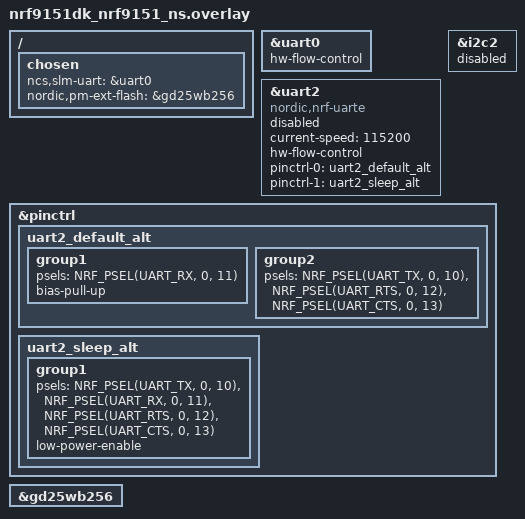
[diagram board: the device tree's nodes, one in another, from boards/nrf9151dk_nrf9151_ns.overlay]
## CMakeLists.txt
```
#
# Copyright (c) 2019 Nordic Semiconductor
#
# SPDX-License-Identifier: LicenseRef-Nordic-5-Clause
#

cmake_minimum_required(VERSION 3.20.0)

find_package(Zephyr REQUIRED HINTS $ENV{ZEPHYR_BASE})
project(serial_lte_modem)

# NORDIC SDK APP START
target_sources(app PRIVATE src/main.c)
target_sources(app PRIVATE src/slm_util.c)
target_sources(app PRIVATE src/slm_settings.c)
target_sources(app PRIVATE src/slm_at_host.c)
target_sources(app PRIVATE src/slm_at_commands.c)
target_sources_ifdef(CONFIG_SLM_SOCKET app PRIVATE src/slm_at_socket.c)
target_sources_ifdef(CONFIG_SLM_TCP_PROXY app PRIVATE src/slm_at_tcp_proxy.c)
target_sources_ifdef(CONFIG_SLM_UDP_PROXY app PRIVATE src/slm_at_udp_proxy.c)
target_sources_ifdef(CONFIG_SLM_ICMP app PRIVATE src/slm_at_icmp.c)
target_sources(app PRIVATE src/slm_at_fota.c)
target_sources(app PRIVATE src/slm_uart_handler.c)
# NORDIC SDK APP END
target_sources_ifdef(CONFIG_SLM_SMS app PRIVATE src/slm_at_sms.c)
target_sources_ifdef(CONFIG_SLM_PPP app PRIVATE src/slm_ppp.c)
target_sources_ifdef(CONFIG_SLM_CMUX app PRIVATE src/slm_cmux.c)

add_subdirectory_ifdef(CONFIG_SLM_GNSS src/gnss)
add_subdirectory_ifdef(CONFIG_SLM_NRF_CLOUD src/nrfcloud)
add_subdirectory_ifdef(CONFIG_SLM_MQTTC src/mqtt_c)
add_subdirectory_ifdef(CONFIG_SLM_HTTPC src/http_c)
add_subdirectory_ifdef(CONFIG_SLM_TWI src/twi)
add_subdirectory_ifdef(CONFIG_SLM_GPIO src/gpio)
add_subdirectory_ifdef(CONFIG_SLM_CARRIER src/lwm2m_carrier)
add_subdirectory_ifdef(CONFIG_SLM_NATIVE_TLS src/nativetls)
if (CONFIG_SLM_FTPC OR CONFIG_SLM_TFTPC)
        add_subdirectory(src/ftp_c)
endif()

zephyr_include_directories(src)
```

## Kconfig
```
#
# Copyright (c) 2019 Nordic Semiconductor
#
# SPDX-License-Identifier: LicenseRef-Nordic-5-Clause
#

source "Kconfig.zephyr"

menu "Nordic Serial LTE Modem"

config SLM_CUSTOMER_VERSION
	string "Customer version string"
	help
	   This version is reported together with baseline versions by AT command "#XSLMVER".

config SLM_AT_MAX_PARAM
	int "Maximum number of parameters in AT command"
	default 42

#
# external XTAL for UART
#
config SLM_EXTERNAL_XTAL
	bool "Use external XTAL for UARTE"
	default y

#
# AT command terminator
#
choice
	prompt "Termination mode"
	default SLM_CR_LF_TERMINATION
	help
		Sets the command terminator used by the serial terminal.
		Available options are:
		-  CR termination
		-  LF termination
		-  CR+LF termination
	config SLM_CR_TERMINATION
		bool "CR termination"
	config SLM_LF_TERMINATION
		bool "LF termination"
	config SLM_CR_LF_TERMINATION
		bool "CR+LF termination"
endchoice

#
# UART buffers (when CMUX is not in use)
#
config SLM_UART_RX_BUF_COUNT
	int "Receive buffers for UART"
	range 2 4
	default 3
	help
	  Amount of buffers for receiving (RX) UART traffic.
	  If the buffers are full, UART RX will be disabled until the buffers are processed.
	  These buffers are not used when CMUX is in use.

config SLM_UART_RX_BUF_SIZE
	int "Receive buffer size for UART"
	range 128 4096
	default 256
	help
	  Amount of received (RX), unprocessed, UART traffic that can be held by single buffer.
	  These buffers are not used when CMUX is in use.

config SLM_UART_TX_BUF_SIZE
	int "Send buffer size for UART"
	range 128 4096
	default 256
	help
	  Amount of UART traffic waiting to be sent (TX), that can be held.
	  If the buffers are full, will send synchronously.
	  These buffers are not used when CMUX is in use.

#
# GPIO functionality
#
config SLM_START_SLEEP
	bool "Enter sleep on startup"
	help
	  If enabled, the SiP is put into deep sleep when powered on.
	  It can then be started using SLM_POWER_PIN.

config SLM_POWER_PIN
	int "Power pin"
	default -1
	help
	  Interface GPIO pin used to put the SiP into deep sleep and wake up from it or exit idle.
	  The pin is configured with a pull up and must be pulled down shortly to perform one power off or wake up operation.

config SLM_INDICATE_PIN
	int "Indicate pin"
	default -1
	help
	  Interface GPIO pin used to indicate that data is available when SLM is idle (after #XSLEEP=2 AT command).

config SLM_INDICATE_TIME
	int "Indication period"
	default 100
	help
	  GPIO active indication time in milliseconds. This setting specify the period length for the pin to be active

#
# LTE network automatic attach
#
config SLM_AUTO_CONNECT
	bool "Automatically connect to the LTE network on start-up or after a reset"
	help
	  Enables automatic connection to the LTE network using the PDN configuration defined in 'slm_auto_connect.h'.

#
# TCP/TLS proxy
#
config SLM_TCP_POLL_TIME
	int "Poll time-out in seconds for TCP connection"
	default 10

config SLM_UDP_POLL_TIME
	int "Poll time-out in seconds for UDP connection"
	default 10

#
# Data mode
#
config SLM_DATAMODE_TERMINATOR
	string "Pattern string to terminate data mode"
	default "+++"
	help
	  Use a pattern to terminate data mode

config SLM_DATAMODE_URC
	bool "Send URC in data mode"
	help
	  Report result of data mode sending

config SLM_DATAMODE_BUF_SIZE
	int "Buffer size for data mode"
	range 1024 8192
	default 4096
	help
	  Size of the buffer for data received in data mode.

#
# Configurable services
#
config SLM_SOCKET
	bool "Socket support in SLM"
	default y

config SLM_TCP_PROXY
	bool "TCP proxy support in SLM"
	default y

config SLM_UDP_PROXY
	bool "UDP proxy support in SLM"
	default y

config SLM_ICMP
	bool "ICMP support in SLM"
	default y

config SLM_SMS
	bool "SMS support in SLM"
	default y
	select SMS
	help
	  Support SMS send/receive in plain text

config SLM_GNSS
	bool "GNSS support in SLM"
	default y

config SLM_NRF_CLOUD
	bool "nRF Cloud support in SLM"
	default y

config SLM_FULL_FOTA
	bool "Full modem FOTA support in SLM"
	default n
	depends on !BOARD_THINGY91_NRF9160_NS

config SLM_PPP
	bool "PPP support in SLM"
	help
	  When enabled, SLM automatically brings up/down the PPP link
	  when the LTE link (default PDN) is connected/disconnected,
	  regardless of what is done with AT#XPPP.

if SLM_PPP

config SLM_PPP_FALLBACK_MTU
	int "Fallback MTU to be used by PPP"
	default 1280
	help
	  PPP tries to retrieve the cellular link MTU from the modem (using `AT+CGCONTRDP=0`).
	  If no MTU is returned by the modem, this value will be used as a fallback.
	  The MTU will be used for sending and receiving of data on both the PPP and cellular links.

endif

config SLM_CMUX
	bool "CMUX support in SLM"

config SLM_CMUX_UART_BUFFER_SIZE
	int "UART buffer size for CMUX"
	depends on SLM_CMUX
	default 6000
	help
	  Size of the buffer for data received in CMUX mode.
	  Same buffer size is used for both RX and TX.

if SLM_CMUX && SLM_PPP

config SLM_CMUX_AUTOMATIC_FALLBACK_ON_PPP_STOPPAGE
	bool "AT channel automatic fallback to DLCI 1 when PPP stops."
	help
	  This is mainly intended for compatibility with Zephyr's cellular modem driver.
	  If enabled, when PPP stops (which happens automatically when the LTE link goes down)
	  CMUX will make the AT channel be on DLCI 1. This only has an effect if it had been
	  configured to be elsewhere, e.g. with AT#XCMUX=2.

endif

if SLM_CMUX || SLM_PPP

config SLM_MODEM_PIPE_TIMEOUT
	int "Timeout for the CMUX and PPP modem pipe operations in seconds"
	default 10

endif

config SLM_SKIP_READY_MSG
	bool "Skip ready message"
	help
	  Skip sending the ready message when the application is powered on.


module = SLM
module-str = serial modem
source "${ZEPHYR_BASE}/subsys/logging/Kconfig.template.log_config"

rsource "src/ftp_c/Kconfig"
rsource "src/mqtt_c/Kconfig"
rsource "src/http_c/Kconfig"
rsource "src/twi/Kconfig"
rsource "src/gpio/Kconfig"
rsource "src/lwm2m_carrier/Kconfig"
rsource "src/gnss/Kconfig"
rsource "src/nativetls/Kconfig"

endmenu
```

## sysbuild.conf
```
#
# Copyright (c) 2023 Nordic Semiconductor
#
# SPDX-License-Identifier: LicenseRef-Nordic-5-Clause
#

SB_CONFIG_BOOTLOADER_MCUBOOT=y
#SB_CONFIG_PM_EXTERNAL_FLASH_MCUBOOT_SECONDARY=y
```

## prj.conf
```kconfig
#
# Copyright (c) 2020 Nordic Semiconductor ASA
#
# SPDX-License-Identifier: LicenseRef-Nordic-5-Clause
#
# General config
CONFIG_LOG=y
CONFIG_LOG_DEFAULT_LEVEL=3
CONFIG_STACK_SENTINEL=y
CONFIG_PICOLIBC_IO_FLOAT=y
CONFIG_RING_BUFFER=y
CONFIG_REBOOT=y
CONFIG_EVENTFD=y

# Network
CONFIG_NETWORKING=y
CONFIG_NET_SOCKETS=y
CONFIG_NET_NATIVE=n
CONFIG_NET_IPV4=y
CONFIG_NET_IPV6=y

# Modem library
CONFIG_NRF_MODEM_LIB=y
CONFIG_AT_CMD_CUSTOM=y
# Align the max FD entry to NRF_MODEM_MAX_SOCKET_COUNT(8)
CONFIG_ZVFS_OPEN_MAX=8

# Handle modem fault
CONFIG_NRF_MODEM_LIB_ON_FAULT_APPLICATION_SPECIFIC=y

# Use GPIO
CONFIG_GPIO=y
CONFIG_GPIO_NRFX=y

# UART interface
CONFIG_SERIAL=y
CONFIG_UART_USE_RUNTIME_CONFIGURE=y
CONFIG_UART_ASYNC_API=y
CONFIG_NRFX_TIMER2=y

# Stacks and heaps
CONFIG_MAIN_STACK_SIZE=4096
CONFIG_HEAP_MEM_POOL_SIZE=16384
CONFIG_SYSTEM_WORKQUEUE_STACK_SIZE=4096
CONFIG_AT_MONITOR_HEAP_SIZE=4096

# Device power management
CONFIG_PM_DEVICE=y

# FOTA
CONFIG_HTTP_PARSER_URL=y
CONFIG_FOTA_DOWNLOAD=y
CONFIG_FOTA_DOWNLOAD_PROGRESS_EVT=y
CONFIG_DFU_TARGET=y
CONFIG_DOWNLOAD_CLIENT=y
CONFIG_DOWNLOAD_CLIENT_STACK_SIZE=4096
CONFIG_DOWNLOAD_CLIENT_MAX_FILENAME_SIZE=2048
CONFIG_BOOTLOADER_MCUBOOT=y
CONFIG_IMG_MANAGER=y

# FLASH
CONFIG_FLASH=y
CONFIG_FLASH_PAGE_LAYOUT=y
CONFIG_FLASH_MAP=y
CONFIG_STREAM_FLASH=y
CONFIG_MPU_ALLOW_FLASH_WRITE=y
CONFIG_IMG_ERASE_PROGRESSIVELY=y

# Settings
CONFIG_SETTINGS=y
CONFIG_SETTINGS_NVS=y
CONFIG_NVS=y

# nRF Cloud
CONFIG_NRF_CLOUD_MQTT=y
CONFIG_NRF_CLOUD_FOTA=n
CONFIG_NRF_CLOUD_AGNSS=y
CONFIG_NRF_CLOUD_AGNSS_FILTERED=n
CONFIG_NRF_CLOUD_PGPS=n
CONFIG_NRF_CLOUD_LOCATION=y
CONFIG_NRF_CLOUD_LOG_LEVEL_INF=y
CONFIG_NRF_CLOUD_GPS_LOG_LEVEL_INF=y
CONFIG_NRF_CLOUD_CLIENT_ID_SRC_INTERNAL_UUID=y
CONFIG_NRF_CLOUD_WIFI_LOCATION_ENCODE_OPT_MAC_RSSI=y
CONFIG_DATE_TIME=y
CONFIG_MODEM_INFO=y
CONFIG_MODEM_INFO_ADD_DATE_TIME=n

# UUID and JWT
CONFIG_MODEM_JWT=y

# MQTT client
#CONFIG_MQTT_KEEPALIVE=60
CONFIG_MQTT_CLEAN_SESSION=y

# AT command helper libraries
CONFIG_AT_PARSER=y
CONFIG_AT_MONITOR=y

# Disable TF-M logging.
# TF-M log sending will block until remote end is ready, when HWFC is used on UART1.
CONFIG_TFM_LOG_LEVEL_SILENCE=y

#
# SLM-specific configurations
#
CONFIG_SLM_CUSTOMER_VERSION=""
CONFIG_SLM_EXTERNAL_XTAL=n

# debug options
#CONFIG_ASSERT=y
#CONFIG_LOG_BUFFER_SIZE=16384
#CONFIG_SLM_LOG_LEVEL_DBG=y
#CONFIG_LOG_PRINTK=n
#CONFIG_LOG_MODE_IMMEDIATE=y

# For using external GNSS antenna
#CONFIG_MODEM_ANTENNA=y
#CONFIG_MODEM_ANTENNA_GNSS_EXTERNAL=y
```

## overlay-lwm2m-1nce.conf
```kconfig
#
# Copyright (c) 2024 Nordic Semiconductor ASA
#
# SPDX-License-Identifier: LicenseRef-Nordic-5-Clause
#

CONFIG_SLM_AUTO_CONNECT=y
CONFIG_SLM_LWM2M_ENDPOINT_CLIENT_NAME_ICCID=y
CONFIG_SLM_CUSTOMER_VERSION="MECC project"

CONFIG_LWM2M_CLIENT_UTILS_SERVER="coaps://lwm2m.os.1NCE.com:5684"
CONFIG_LWM2M_CLIENT_UTILS_ADV_FIRMWARE_UPDATE_OBJ_SUPPORT=n
CONFIG_LWM2M_CLIENT_UTILS_CONN_STAT_OBJ_SUPPORT=y
```

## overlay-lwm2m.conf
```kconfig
#
# Copyright (c) 2024 Nordic Semiconductor ASA
#
# SPDX-License-Identifier: LicenseRef-Nordic-5-Clause
#

CONFIG_SLM_AUTO_CONNECT=y

CONFIG_SLM_LWM2M=y
CONFIG_SLM_LWM2M_AUTO_STARTUP=y
CONFIG_SLM_LWM2M_PSK=""

CONFIG_PDN=y

CONFIG_LWM2M=y
CONFIG_LWM2M_DNS_SUPPORT=y
CONFIG_LWM2M_DTLS_SUPPORT=y
CONFIG_LWM2M_COAP_BLOCK_SIZE=512
CONFIG_LWM2M_COAP_MAX_MSG_SIZE=1280
CONFIG_LWM2M_TICKLESS=y
CONFIG_LWM2M_TLS_SESSION_CACHING=y
CONFIG_LWM2M_RW_OMA_TLV_SUPPORT=y
CONFIG_LWM2M_RD_CLIENT_SUPPORT_BOOTSTRAP=y
CONFIG_LWM2M_RD_CLIENT_SUSPEND_SOCKET_AT_IDLE=y

CONFIG_LWM2M_VERSION_1_1=y
CONFIG_LWM2M_RW_SENML_CBOR_SUPPORT=y

CONFIG_LWM2M_CLIENT_UTILS=y
CONFIG_LWM2M_CLIENT_UTILS_SERVER=""
CONFIG_LWM2M_CLIENT_UTILS_SECURITY_OBJ_SUPPORT=y
CONFIG_LWM2M_CLIENT_UTILS_DEVICE_OBJ_SUPPORT=y
CONFIG_LWM2M_CLIENT_UTILS_CONN_MON_OBJ_SUPPORT=y
CONFIG_LWM2M_CLIENT_UTILS_FIRMWARE_UPDATE_OBJ_SUPPORT=y
CONFIG_LWM2M_CLIENT_UTILS_ADV_FIRMWARE_UPDATE_OBJ_SUPPORT=n
CONFIG_LWM2M_CLIENT_UTILS_LOCATION_OBJ_SUPPORT=n
CONFIG_LWM2M_CLIENT_UTILS_CELL_CONN_OBJ_SUPPORT=y
CONFIG_LWM2M_CLIENT_UTILS_BINARYAPPDATA_OBJ_SUPPORT=y

# Enable DTLS Connection Identifier and TLS session caching
# to prevent doing a full TLS handshake for every send.
CONFIG_LWM2M_TLS_SESSION_CACHING=y
CONFIG_LWM2M_DTLS_CID=y

# Set uptime to 12 hours.
# Update every 60 minutes (3600 s)
CONFIG_LWM2M_ENGINE_DEFAULT_LIFETIME=43200
CONFIG_LWM2M_UPDATE_PERIOD=3600
CONFIG_LWM2M_SECONDS_TO_UPDATE_EARLY=60

# LwM2M Queue Mode
CONFIG_LWM2M_QUEUE_MODE_ENABLED=y
CONFIG_LWM2M_RD_CLIENT_STOP_POLLING_AT_IDLE=y
# Sets the duration that the lwm2m engine will be polling for data after transmission before
# the socket is closed.
CONFIG_LWM2M_QUEUE_MODE_UPTIME=30

# Enable Release Assistance Indication
CONFIG_LWM2M_CLIENT_UTILS_RAI=y

# Support HEX style PSK values (double the size + NULL char)
CONFIG_LWM2M_SECURITY_KEY_SIZE=33
CONFIG_LWM2M_SECURITY_INSTANCE_COUNT=2

CONFIG_COAP_EXTENDED_OPTIONS_LEN=y
CONFIG_COAP_EXTENDED_OPTIONS_LEN_VALUE=40

# Because of SenML CBOR
CONFIG_ZCBOR=y
CONFIG_ZCBOR_CANONICAL=y

# Because of CONFIG_LWM2M_DTLS_SUPPORT, the following options are required
CONFIG_MODEM_KEY_MGMT=y

# Because of CONFIG_LWM2M_TICKLESS, the following options are required
CONFIG_NET_SOCKETPAIR=y

# Until lwm2m_client_utils build without LTE_LINK_CONTROL
CONFIG_LTE_LINK_CONTROL=y

# Disable modules not needed
CONFIG_SLM_NRF_CLOUD=n
CONFIG_SLM_SMS=n
CONFIG_SLM_GNSS=n
CONFIG_SLM_FTPC=n
CONFIG_SLM_TFTPC=n
CONFIG_SLM_MQTTC=n
CONFIG_SLM_HTTPC=n
```

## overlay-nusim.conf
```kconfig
# Custom SLM version
CONFIG_SLM_CUSTOMER_VERSION="nuSIM v0.1.0"

# Enable nuSIM Application LIB
CONFIG_LIB_NUSIM=y

# Turn off interrupt driven UART (enabled in nuSIM)
CONFIG_UART_INTERRUPT_DRIVEN=n

# Disable commands to save app flash space
CONFIG_SLM_FTPC=n
CONFIG_SLM_TFTPC=n
CONFIG_SLM_HTTPC=n
CONFIG_SLM_MQTTC=n
CONFIG_SLM_SMS=n
```

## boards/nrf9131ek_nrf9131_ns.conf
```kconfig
#
# Copyright (c) 2024 Nordic Semiconductor ASA
#
# SPDX-License-Identifier: LicenseRef-Nordic-5-Clause
#

# Configuration file for nRF9131EK.
# This file is merged with prj.conf in the application folder, and options
# set here will take precedence if they are present in both files.

# Segger RTT
CONFIG_USE_SEGGER_RTT=y
# Where console messages (printk) are output.
# By itself, SLM does not output any.
CONFIG_RTT_CONSOLE=y
CONFIG_UART_CONSOLE=n
# Where SLM logs are output.
CONFIG_LOG_BACKEND_RTT=y
CONFIG_LOG_BACKEND_UART=n

CONFIG_UART_0_NRF_HW_ASYNC_TIMER=2
CONFIG_UART_0_NRF_HW_ASYNC=y
CONFIG_SLM_POWER_PIN=28
CONFIG_SLM_INDICATE_PIN=0
```

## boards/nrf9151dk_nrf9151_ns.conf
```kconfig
#
# Copyright (c) 2024 Nordic Semiconductor ASA
#
# SPDX-License-Identifier: LicenseRef-Nordic-5-Clause
#

# Configuration file for nRF9151DK.
# This file is merged with prj.conf in the application folder, and options
# set here will take precedence if they are present in both files.

# Segger RTT
CONFIG_USE_SEGGER_RTT=y
# Where console messages (printk) are output.
# By itself, SLM does not output any.
CONFIG_RTT_CONSOLE=y
CONFIG_UART_CONSOLE=n
# Where SLM logs are output.
CONFIG_LOG_BACKEND_RTT=y
CONFIG_LOG_BACKEND_UART=n

# Use UART_0 (when working with PC terminal)
# unmask the following config
CONFIG_UART_0_NRF_HW_ASYNC_TIMER=2
CONFIG_UART_0_NRF_HW_ASYNC=y
CONFIG_SLM_POWER_PIN=8
CONFIG_SLM_INDICATE_PIN=0

# Use UART_2 (when working with external MCU)
# unmask the following config
#CONFIG_UART_2_NRF_HW_ASYNC_TIMER=2
#CONFIG_UART_2_NRF_HW_ASYNC=y
#CONFIG_SLM_POWER_PIN=31
#CONFIG_SLM_INDICATE_PIN=30
```

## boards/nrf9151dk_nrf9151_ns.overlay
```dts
/*
 * Copyright (c) 2024 Nordic Semiconductor ASA
 *
 * SPDX-License-Identifier: LicenseRef-Nordic-5-Clause
 */

 / {
	chosen {
		ncs,slm-uart = &uart0;
		nordic,pm-ext-flash = &gd25wb256;
	};
};

&uart0 {
	status = "okay";
	hw-flow-control;
};

&uart2 {
	compatible = "nordic,nrf-uarte";
	current-speed = <115200>;
	status = "disabled";
	hw-flow-control;

	pinctrl-0 = <&uart2_default_alt>;
	pinctrl-1 = <&uart2_sleep_alt>;
	pinctrl-names = "default", "sleep";
};

&i2c2 {
	status = "disabled";
};

&pinctrl {
	uart2_default_alt: uart2_default_alt {
		group1 {
			psels = <NRF_PSEL(UART_RX, 0, 11)>;
			bias-pull-up;
		};
		group2 {
			psels = <NRF_PSEL(UART_TX, 0, 10)>,
				<NRF_PSEL(UART_RTS, 0, 12)>,
				<NRF_PSEL(UART_CTS, 0, 13)>;
		};
	};

	uart2_sleep_alt: uart2_sleep_alt {
		group1 {
			psels = <NRF_PSEL(UART_TX, 0, 10)>,
				<NRF_PSEL(UART_RX, 0, 11)>,
				<NRF_PSEL(UART_RTS, 0, 12)>,
				<NRF_PSEL(UART_CTS, 0, 13)>;
			low-power-enable;
		};
	};
};

/* Enable external flash */
&gd25wb256 {
	status = "okay";
};
```

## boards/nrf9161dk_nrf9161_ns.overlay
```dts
/*
 * Copyright (c) 2023 Nordic Semiconductor ASA
 *
 * SPDX-License-Identifier: LicenseRef-Nordic-5-Clause
 */

/ {
	chosen {
		ncs,slm-uart = &uart0;
		nordic,pm-ext-flash = &gd25wb256;
	};
};

&uart0 {
	status = "okay";
	hw-flow-control;
};

&uart2 {
	compatible = "nordic,nrf-uarte";
	current-speed = <115200>;
	status = "disabled";
	hw-flow-control;

	pinctrl-0 = <&uart2_default_alt>;
	pinctrl-1 = <&uart2_sleep_alt>;
	pinctrl-names = "default", "sleep";
};

&i2c2 {
	status = "disabled";
};

&pinctrl {
	uart2_default_alt: uart2_default_alt {
		group1 {
			psels = <NRF_PSEL(UART_RX, 0, 11)>;
			bias-pull-up;
		};
		group2 {
			psels = <NRF_PSEL(UART_TX, 0, 10)>,
				<NRF_PSEL(UART_RTS, 0, 12)>,
				<NRF_PSEL(UART_CTS, 0, 13)>;
		};
	};

	uart2_sleep_alt: uart2_sleep_alt {
		group1 {
			psels = <NRF_PSEL(UART_TX, 0, 10)>,
				<NRF_PSEL(UART_RX, 0, 11)>,
				<NRF_PSEL(UART_RTS, 0, 12)>,
				<NRF_PSEL(UART_CTS, 0, 13)>;
			low-power-enable;
		};
	};
};

/* Enable external flash */
&gd25wb256 {
	status = "okay";
};
```

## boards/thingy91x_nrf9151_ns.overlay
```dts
/*
 * Copyright (c) 2024 Nordic Semiconductor ASA
 *
 * SPDX-License-Identifier: LicenseRef-Nordic-5-Clause
 */

/ {
	chosen {
		ncs,slm-uart = &uart0;
	};
};

&uart0 {
	status = "okay";
};

&uart1 {
	status = "okay";
	hw-flow-control;
};

&button0 {
	status = "disabled";
};
```

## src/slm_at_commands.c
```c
/*
 * Copyright (c) 2021 Nordic Semiconductor ASA
 *
 * SPDX-License-Identifier: LicenseRef-Nordic-5-Clause
 */
#include <ctype.h>
#include <stdio.h>
#include <string.h>
#include <strings.h>
#include <zephyr/init.h>
#include <zephyr/drivers/uart.h>
#include <zephyr/kernel.h>
#include <zephyr/logging/log_ctrl.h>
#include <zephyr/sys/reboot.h>
#include <zephyr/sys/util.h>
#include <zephyr/types.h>
#include <dfu/dfu_target.h>
#include <modem/at_parser.h>
#include <modem/lte_lc.h>
#include <modem/modem_jwt.h>
#include <modem/nrf_modem_lib.h>
#include "nrf_modem.h"
#include "ncs_version.h"

#include "slm_util.h"
#include "slm_settings.h"
#include "slm_at_host.h"
#if defined(CONFIG_SLM_TCP_PROXY)
#include "slm_at_tcp_proxy.h"
#endif
#if defined(CONFIG_SLM_UDP_PROXY)
#include "slm_at_udp_proxy.h"
#endif
#if defined(CONFIG_SLM_SOCKET)
#include "slm_at_socket.h"
#endif
#if defined(CONFIG_SLM_ICMP)
#include "slm_at_icmp.h"
#endif
#if defined(CONFIG_SLM_SMS)
#include "slm_at_sms.h"
#endif
#include "slm_at_fota.h"
#if defined(CONFIG_SLM_NATIVE_TLS)
#include "slm_at_cmng.h"
#endif
#if defined(CONFIG_SLM_NRF_CLOUD)
#include "slm_at_nrfcloud.h"
#endif
#if defined(CONFIG_SLM_GNSS)
#include "slm_at_gnss.h"
#endif
#if defined(CONFIG_SLM_FTPC)
#include "slm_at_ftp.h"
#endif
#if defined(CONFIG_SLM_MQTTC)
#include "slm_at_mqtt.h"
#endif
#if defined(CONFIG_SLM_HTTPC)
#include "slm_at_httpc.h"
#endif
#if defined(CONFIG_SLM_TWI)
#include "slm_at_twi.h"
#endif
#if defined(CONFIG_SLM_GPIO)
#include "slm_at_gpio.h"
#endif
#if defined(CONFIG_SLM_CARRIER)
#include "slm_at_carrier.h"
#endif
#if defined(CONFIG_LWM2M_CARRIER_SETTINGS)
#include "slm_at_carrier_cfg.h"
#endif
#if defined(CONFIG_SLM_PPP)
#include "slm_ppp.h"
#endif
#if defined(CONFIG_SLM_CMUX)
#include "slm_cmux.h"
#endif

LOG_MODULE_REGISTER(slm_at, CONFIG_SLM_LOG_LEVEL);

/** @brief Shutdown modes. */
enum sleep_modes {
	SLEEP_MODE_INVALID,
	SLEEP_MODE_DEEP,
	SLEEP_MODE_IDLE
};

#if POWER_PIN_IS_ENABLED
static struct {
	struct k_work_delayable work;
	uint32_t mode;
} sleep_control;
#endif

bool verify_datamode_control(uint16_t time_limit, uint16_t *time_limit_min);

bool slm_is_modem_functional_mode(enum lte_lc_func_mode mode)
{
	int cfun;
	int rc = slm_util_at_scanf("AT+CFUN?", "+CFUN: %d", &cfun);

	return (rc == 1 && cfun == mode);
}

int slm_power_off_modem(void)
{
	/* "[...] there may be a delay until modem is disconnected from the network."
	 * https://infocenter.nordicsemi.com/topic/ps_nrf9160/chapters/pmu/doc/operationmodes/system_off_mode.html
	 * This will return once the modem responds, which means it has actually stopped.
	 * This has been observed to take between 1 and 2 seconds when it is not already stopped.
	 */
	return slm_util_at_printf("AT+CFUN=0");
}

SLM_AT_CMD_CUSTOM(xslmver, "AT#XSLMVER", handle_at_slmver);
static int handle_at_slmver(enum at_parser_cmd_type cmd_type, struct at_parser *, uint32_t)
{
	int ret = -EINVAL;

	if (cmd_type == AT_PARSER_CMD_TYPE_SET) {
		char *libmodem = nrf_modem_build_version();

		if (strlen(CONFIG_SLM_CUSTOMER_VERSION) > 0) {
			rsp_send("\r\n#XSLMVER: %s,\"%s\",\"%s\"\r\n",
				 STRINGIFY(NCS_VERSION_STRING), libmodem,
				 CONFIG_SLM_CUSTOMER_VERSION);
		} else {
			rsp_send("\r\n#XSLMVER: %s,\"%s\"\r\n",
				 STRINGIFY(NCS_VERSION_STRING), libmodem);
		}
		ret = 0;
	}

	return ret;
}

#if POWER_PIN_IS_ENABLED

static void go_sleep_wk(struct k_work *)
{
	if (sleep_control.mode == SLEEP_MODE_IDLE) {
		if (slm_at_host_power_off() == 0) {
			slm_enter_idle();
		} else {
			LOG_ERR("failed to power off UART");
		}
	} else if (sleep_control.mode == SLEEP_MODE_DEEP) {
		slm_enter_sleep();
	}
}

SLM_AT_CMD_CUSTOM(xsleep, "AT#XSLEEP", handle_at_sleep);
static int handle_at_sleep(enum at_parser_cmd_type cmd_type, struct at_parser *parser,
			   uint32_t)
{
	int ret = -EINVAL;

	if (cmd_type == AT_PARSER_CMD_TYPE_SET) {
		ret = at_parser_num_get(parser, 1, &sleep_control.mode);
		if (ret) {
			return -EINVAL;
		}
		if (sleep_control.mode == SLEEP_MODE_DEEP ||
		    sleep_control.mode == SLEEP_MODE_IDLE) {
			k_work_reschedule(&sleep_control.work, SLM_UART_RESPONSE_DELAY);
		} else {
			ret = -EINVAL;
		}
	} else if (cmd_type == AT_PARSER_CMD_TYPE_TEST) {
		rsp_send("\r\n#XSLEEP: (%d,%d)\r\n", SLEEP_MODE_DEEP, SLEEP_MODE_IDLE);
		ret = 0;
	}

	return ret;
}

#endif /* POWER_PIN_IS_ENABLED */

static void final_call(void (*func)(void))
{
	/* Delegate the final call to a worker so that the "OK" response is properly sent. */
	static struct k_work_delayable worker;

	k_work_init_delayable(&worker, (k_work_handler_t)func);
	k_work_schedule(&worker, SLM_UART_RESPONSE_DELAY);
}

static void slm_shutdown(void)
{
	slm_at_host_uninit();
	slm_power_off_modem();
	LOG_PANIC();
	slm_enter_shutdown();
}

SLM_AT_CMD_CUSTOM(xshutdown, "AT#XSHUTDOWN", handle_at_shutdown);
static int handle_at_shutdown(enum at_parser_cmd_type cmd_type, struct at_parser *, uint32_t)
{
	if (cmd_type != AT_PARSER_CMD_TYPE_SET) {
		return -EINVAL;
	}

	final_call(slm_shutdown);
	return 0;
}

FUNC_NORETURN void slm_reset(void)
{
	slm_at_host_uninit();
	slm_power_off_modem();
	LOG_PANIC();
	sys_reboot(SYS_REBOOT_COLD);
}

SLM_AT_CMD_CUSTOM(xreset, "AT#XRESET", handle_at_reset);
static int handle_at_reset(enum at_parser_cmd_type cmd_type, struct at_parser *, uint32_t)
{
	if (cmd_type != AT_PARSER_CMD_TYPE_SET) {
		return -EINVAL;
	}

	final_call(slm_reset);
	return 0;
}

static void slm_modemreset(void)
{
	/* The modem must be put in minimal function mode before being shut down. */
	slm_power_off_modem();

	unsigned int step = 1;
	int ret;

	ret = nrf_modem_lib_shutdown();
	if (ret != 0) {
		goto out;
	}
	++step;

#if defined(CONFIG_SLM_FULL_FOTA)
	if (slm_modem_full_fota) {
		slm_finish_modem_full_fota();
	}
#endif

	ret = nrf_modem_lib_init();

	if (slm_fota_type & DFU_TARGET_IMAGE_TYPE_ANY_MODEM) {
		slm_fota_post_process();
	}

out:
	if (ret) {
		/* Error; print the step that failed and its error code. */
		rsp_send("\r\n#XMODEMRESET: %u,%d\r\n", step, ret);
	} else {
		rsp_send("\r\n#XMODEMRESET: 0\r\n");
	}
	rsp_send_ok();
}

SLM_AT_CMD_CUSTOM(xmodemreset, "AT#XMODEMRESET", handle_at_modemreset);
static int handle_at_modemreset(enum at_parser_cmd_type cmd_type, struct at_parser *, uint32_t)
{
	if (cmd_type != AT_PARSER_CMD_TYPE_SET) {
		return -EINVAL;
	}

	/* Return immediately to allow the custom command handling in libmodem to finish processing,
	 * before restarting libmodem.
	 */
	final_call(slm_modemreset);

	return -SILENT_AT_COMMAND_RET;
}

SLM_AT_CMD_CUSTOM(xuuid, "AT#XUUID", handle_at_uuid);
static int handle_at_uuid(enum at_parser_cmd_type cmd_type, struct at_parser *, uint32_t)
{
	int ret;

	if (cmd_type != AT_PARSER_CMD_TYPE_SET) {
		return -EINVAL;
	}

	struct nrf_device_uuid dev = {0};

	ret = modem_jwt_get_uuids(&dev, NULL);
	if (ret) {
		LOG_ERR("Get device UUID error: %d", ret);
	} else {
		rsp_send("\r\n#XUUID: %s\r\n", dev.str);
	}

	return ret;
}

SLM_AT_CMD_CUSTOM(xdatactrl, "AT#XDATACTRL", handle_at_datactrl);
static int handle_at_datactrl(enum at_parser_cmd_type cmd_type, struct at_parser *parser,
			      uint32_t)
{
	int ret = 0;
	uint16_t time_limit, time_limit_min;

	switch (cmd_type) {
	case AT_PARSER_CMD_TYPE_SET:
		ret = at_parser_num_get(parser, 1, &time_limit);
		if (ret) {
			return ret;
		}
		if (time_limit > 0 && verify_datamode_control(time_limit, NULL)) {
			slm_datamode_time_limit = time_limit;
		} else {
			return -EINVAL;
		}
		break;

	case AT_PARSER_CMD_TYPE_READ:
		(void)verify_datamode_control(slm_datamode_time_limit, &time_limit_min);
		rsp_send("\r\n#XDATACTRL: %d,%d\r\n", slm_datamode_time_limit, time_limit_min);
		break;

	case AT_PARSER_CMD_TYPE_TEST:
		rsp_send("\r\n#XDATACTRL=<time_limit>\r\n");
		break;

	default:
		break;
	}

	return ret;
}

SLM_AT_CMD_CUSTOM(xclac, "AT#XCLAC", handle_at_clac);
static int handle_at_clac(enum at_parser_cmd_type cmd_type, struct at_parser *, uint32_t)
{
	if (cmd_type != AT_PARSER_CMD_TYPE_SET) {
		return -EINVAL;
	}

	/* Use AT_CMD_CUSTOM listing for extracting SLM AT commands. */
	extern struct nrf_modem_at_cmd_custom _nrf_modem_at_cmd_custom_list_start[];
	extern struct nrf_modem_at_cmd_custom _nrf_modem_at_cmd_custom_list_end[];
	size_t cmd_custom_count = _nrf_modem_at_cmd_custom_list_end -
				  _nrf_modem_at_cmd_custom_list_start;
	size_t base_cmd_len[cmd_custom_count];

	memset(base_cmd_len, 0, cmd_custom_count * sizeof(size_t));
	rsp_send("\r\n");
	for (size_t i = 0; i < cmd_custom_count; i++) {
		/* SLM at commands start with AT#X. */
		if (strncasecmp(_nrf_modem_at_cmd_custom_list_start[i].cmd, "AT#X",
				strlen("AT#X"))) {
			continue;
		}
		/* List commands without operations and list each command only once. */
		base_cmd_len[i] = strcspn(_nrf_modem_at_cmd_custom_list_start[i].cmd, "?=");
		bool duplicate = false;

		for (size_t j = 0; j < i; j++) {
			/* Compare length and command as we have AT commands such as
			 * AT#XSEND/AT#XSENDTO, AT#XFTP="whatever"
			 * and AT#XNRFCLOUD[=?]/AT#XNRFCLOUDPOS.
			 */
			if ((base_cmd_len[i] == base_cmd_len[j]) &&
			    !strncasecmp(_nrf_modem_at_cmd_custom_list_start[i].cmd,
					 _nrf_modem_at_cmd_custom_list_start[j].cmd,
					 base_cmd_len[i])) {
				duplicate = true;
				break;
			}
		}

		if (!duplicate) {
			rsp_send("%.*s\r\n", base_cmd_len[i],
				 _nrf_modem_at_cmd_custom_list_start[i].cmd);
		}
	}

	return 0;
}

int slm_at_init(void)
{
	int err;

#if POWER_PIN_IS_ENABLED
	k_work_init_delayable(&sleep_control.work, go_sleep_wk);
#endif

#if defined(CONFIG_SLM_TCP_PROXY)
	err = slm_at_tcp_proxy_init();
	if (err) {
		LOG_ERR("TCP Server could not be initialized: %d", err);
		return -EFAULT;
	}
#endif
#if defined(CONFIG_SLM_UDP_PROXY)
	err = slm_at_udp_proxy_init();
	if (err) {
		LOG_ERR("UDP Server could not be initialized: %d", err);
		return -EFAULT;
	}
#endif
#if defined(CONFIG_SLM_SOCKET)
	err = slm_at_socket_init();
	if (err) {
		LOG_ERR("TCPIP could not be initialized: %d", err);
		return -EFAULT;
	}
#endif
#if defined(CONFIG_SLM_ICMP)
	err = slm_at_icmp_init();
	if (err) {
		LOG_ERR("ICMP could not be initialized: %d", err);
		return -EFAULT;
	}
#endif
#if defined(CONFIG_SLM_SMS)
	err = slm_at_sms_init();
	if (err) {
		LOG_ERR("SMS could not be initialized: %d", err);
		return -EFAULT;
	}
#endif
	err = slm_at_fota_init();
	if (err) {
		LOG_ERR("FOTA could not be initialized: %d", err);
		return -EFAULT;
	}
#if defined(CONFIG_SLM_NRF_CLOUD)
	err = slm_at_nrfcloud_init();
	if (err) {
		LOG_ERR("nRF Cloud could not be initialized: %d", err);
		return -EFAULT;
	}
#endif
#if defined(CONFIG_SLM_GNSS)
	err = slm_at_gnss_init();
	if (err) {
		LOG_ERR("GNSS could not be initialized: %d", err);
		return -EFAULT;
	}
#endif
#if defined(CONFIG_SLM_FTPC)
	err = slm_at_ftp_init();
	if (err) {
		LOG_ERR("FTP could not be initialized: %d", err);
		return -EFAULT;
	}
#endif
#if defined(CONFIG_SLM_MQTTC)
	err = slm_at_mqtt_init();
	if (err) {
		LOG_ERR("MQTT could not be initialized: %d", err);
		return -EFAULT;
	}
#endif
#if defined(CONFIG_SLM_HTTPC)
	err = slm_at_httpc_init();
	if (err) {
		LOG_ERR("HTTP could not be initialized: %d", err);
		return -EFAULT;
	}
#endif
#if defined(CONFIG_SLM_GPIO)
	err = slm_at_gpio_init();
	if (err) {
		LOG_ERR("GPIO could not be initialized: %d", err);
		return -EFAULT;
	}
#endif
#if defined(CONFIG_SLM_TWI)
	err = slm_at_twi_init();
	if (err) {
		LOG_ERR("TWI could not be initialized: %d", err);
		return -EFAULT;
	}
#endif
#if defined(CONFIG_SLM_CARRIER)
	err = slm_at_carrier_init();
	if (err) {
		LOG_ERR("LwM2M carrier could not be initialized: %d", err);
		return -EFAULT;
	}
#endif
#if defined(CONFIG_LWM2M_CARRIER_SETTINGS)
	err = slm_at_carrier_cfg_init();
	if (err) {
		LOG_ERR("LwM2M carrier could not be initialized: %d", err);
		return -EFAULT;
	}
#endif
#if defined(CONFIG_SLM_CMUX)
	slm_cmux_init();
#endif
#if defined(CONFIG_SLM_PPP)
	err = slm_ppp_init();
	if (err) {
		LOG_ERR("PPP initialization failed. (%d)", err);
		return err;
	}
#endif
	return err;
}

void slm_at_uninit(void)
{
	int err;

#if defined(CONFIG_SLM_TCP_PROXY)
	err = slm_at_tcp_proxy_uninit();
	if (err) {
		LOG_WRN("TCP Server could not be uninitialized: %d", err);
	}
#endif
#if defined(CONFIG_SLM_UDP_PROXY)
	err = slm_at_udp_proxy_uninit();
	if (err) {
		LOG_WRN("UDP Server could not be uninitialized: %d", err);
	}
#endif
#if defined(CONFIG_SLM_SOCKET)
	err = slm_at_socket_uninit();
	if (err) {
		LOG_WRN("TCPIP could not be uninitialized: %d", err);
	}
#endif
#if defined(CONFIG_SLM_ICMP)
	err = slm_at_icmp_uninit();
	if (err) {
		LOG_WRN("ICMP could not be uninitialized: %d", err);
	}
#endif
#if defined(CONFIG_SLM_SMS)
	err = slm_at_sms_uninit();
	if (err) {
		LOG_WRN("SMS could not be uninitialized: %d", err);
	}
#endif
	err = slm_at_fota_uninit();
	if (err) {
		LOG_WRN("FOTA could not be uninitialized: %d", err);
	}
#if defined(CONFIG_SLM_NRF_CLOUD)
	err = slm_at_nrfcloud_uninit();
	if (err) {
		LOG_WRN("nRF Cloud could not be uninitialized: %d", err);
	}
#endif
#if defined(CONFIG_SLM_GNSS)
	err = slm_at_gnss_uninit();
	if (err) {
		LOG_WRN("GNSS could not be uninitialized: %d", err);
	}
#endif
#if defined(CONFIG_SLM_FTPC)
	err = slm_at_ftp_uninit();
	if (err) {
		LOG_WRN("FTP could not be uninitialized: %d", err);
	}
#endif
#if defined(CONFIG_SLM_MQTTC)
	err = slm_at_mqtt_uninit();
	if (err) {
		LOG_WRN("MQTT could not be uninitialized: %d", err);
	}
#endif
#if defined(CONFIG_SLM_HTTPC)
	err = slm_at_httpc_uninit();
	if (err) {
		LOG_WRN("HTTP could not be uninitialized: %d", err);
	}
#endif
#if defined(CONFIG_SLM_TWI)
	err = slm_at_twi_uninit();
	if (err) {
		LOG_ERR("TWI could not be uninit: %d", err);
	}
#endif
#if defined(CONFIG_SLM_GPIO)
	err = slm_at_gpio_uninit();
	if (err) {
		LOG_ERR("GPIO could not be uninit: %d", err);
	}
#endif
#if defined(CONFIG_SLM_CARRIER)
	err = slm_at_carrier_uninit();
	if (err) {
		LOG_ERR("LwM2M carrier could not be uninitialized: %d", err);
	}
#endif
}
```

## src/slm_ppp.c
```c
/*
 * Copyright (c) 2023 Nordic Semiconductor ASA
 *
 * SPDX-License-Identifier: LicenseRef-Nordic-5-Clause
 */

#include "slm_ppp.h"
#include "slm_at_host.h"
#include "slm_util.h"
#if defined(CONFIG_SLM_CMUX)
#include "slm_cmux.h"
#endif
#include <modem/pdn.h>
#include <zephyr/modem/ppp.h>
#include <zephyr/modem/backend/uart.h>
#include <zephyr/net/net_if.h>
#include <zephyr/net/ppp.h>
#include <zephyr/posix/sys/socket.h>
#include <zephyr/random/random.h>
#include <assert.h>

LOG_MODULE_REGISTER(slm_ppp, CONFIG_SLM_LOG_LEVEL);

#if defined(CONFIG_SLM_CMUX)
BUILD_ASSERT(!DT_NODE_EXISTS(DT_CHOSEN(ncs_slm_ppp_uart)),
	"When CMUX is enabled PPP is usable only through it so it cannot have its own UART.");
#else
static const struct device *ppp_uart_dev = DEVICE_DT_GET(DT_CHOSEN(ncs_slm_ppp_uart));
#endif
static struct net_if *ppp_iface;

static uint8_t ppp_data_buf[1500];
static struct sockaddr_ll ppp_zephyr_dst_addr;

static struct k_thread ppp_data_passing_thread_id;
static K_THREAD_STACK_DEFINE(ppp_data_passing_thread_stack, KB(2));
static void ppp_data_passing_thread(void*, void*, void*);

static void ppp_controller(struct k_work *work);
enum ppp_action {
	PPP_START,
	PPP_RESTART,
	PPP_STOP
};
struct ppp_work {
	struct k_work work;
	enum ppp_action action;
};
static struct ppp_work ppp_start_work = {
	.work = Z_WORK_INITIALIZER(ppp_controller),
	.action = PPP_START
};
static struct ppp_work ppp_restart_work = {
	.work = Z_WORK_INITIALIZER(ppp_controller),
	.action = PPP_RESTART
};
static struct ppp_work ppp_stop_work = {
	.work = Z_WORK_INITIALIZER(ppp_controller),
	.action = PPP_STOP
};

static bool ppp_peer_connected;

enum ppp_states {
	PPP_STATE_STOPPED,
	PPP_STATE_STARTING,
	PPP_STATE_RUNNING,
	PPP_STATE_STOPPING
};
static atomic_t ppp_state;

MODEM_PPP_DEFINE(ppp_module, NULL, CONFIG_KERNEL_INIT_PRIORITY_DEFAULT,
		 sizeof(ppp_data_buf), sizeof(ppp_data_buf));

static struct modem_pipe *ppp_pipe;

/* We use only the default PDP context. */
enum { PDP_CID = 0 };

enum {
	ZEPHYR_FD_IDX, /* Raw Zephyr socket to pass data to/from the PPP link. */
	MODEM_FD_IDX, /* Raw modem socket to pass data to/from the LTE link. */
	PPP_FDS_COUNT
};
const char *const ppp_socket_names[PPP_FDS_COUNT] = {
	[ZEPHYR_FD_IDX] = "Zephyr",
	[MODEM_FD_IDX] = "modem"
};
static int ppp_fds[PPP_FDS_COUNT] = { -1, -1 };

static bool open_ppp_sockets(void)
{
	int ret;

	ppp_fds[ZEPHYR_FD_IDX] = socket(AF_PACKET, SOCK_RAW | SOCK_NATIVE, IPPROTO_RAW);
	if (ppp_fds[ZEPHYR_FD_IDX] < 0) {
		LOG_ERR("Zephyr socket creation failed (%d).", errno);
		return false;
	}

	ppp_zephyr_dst_addr = (struct sockaddr_ll){
		.sll_family = AF_PACKET,
		.sll_ifindex = net_if_get_by_iface(ppp_iface)
	};
	ret = bind(ppp_fds[ZEPHYR_FD_IDX],
		   (const struct sockaddr *)&ppp_zephyr_dst_addr, sizeof(ppp_zephyr_dst_addr));
	if (ret < 0) {
		LOG_ERR("Failed to bind Zephyr socket (%d).", errno);
		return false;
	}

	ppp_fds[MODEM_FD_IDX] = socket(AF_PACKET, SOCK_RAW, 0);
	if (ppp_fds[MODEM_FD_IDX] < 0) {
		LOG_ERR("Modem socket creation failed (%d).", errno);
		return false;
	}

	return true;
}

static void close_ppp_sockets(void)
{
	for (size_t i = 0; i != ARRAY_SIZE(ppp_fds); ++i) {
		if (ppp_fds[i] < 0) {
			continue;
		}
		if (close(ppp_fds[i])) {
			LOG_WRN("Failed to close %s socket (%d).",
				ppp_socket_names[i], errno);
		}
		ppp_fds[i] = -1;
	}
}

static bool configure_ppp_link_ip_addresses(struct ppp_context *ctx)
{
	static uint8_t ppp_ll_addr[PPP_INTERFACE_IDENTIFIER_LEN];
	uint8_t ll_addr_len;
	char addr4[INET_ADDRSTRLEN];
	char addr6[INET6_ADDRSTRLEN];

	util_get_ip_addr(PDP_CID, addr4, addr6);

	if (*addr4) {
		if (inet_pton(AF_INET, addr4, &ctx->ipcp.my_options.address) != 1) {
			return false;
		}
	} else if (!*addr6) {
		LOG_ERR("No connectivity.");
		return false;
	}

	if (*addr6) {
		struct in6_addr in6;

		if (inet_pton(AF_INET6, addr6, &in6) != 1) {
			return false;
		}
		/* The interface identifier is the last 64 bits of the IPv6 address. */
		BUILD_ASSERT(sizeof(in6) >= sizeof(ppp_ll_addr));
		ll_addr_len = sizeof(ppp_ll_addr);
		memcpy(ppp_ll_addr, (uint8_t *)(&in6 + 1) - ll_addr_len, ll_addr_len);
	} else {
		/* 00-00-5E-00-53-xx as per RFC 7042, as zephyr/drivers/net/ppp.c does. */
		ll_addr_len = 6;
		ppp_ll_addr[0] = 0x00;
		ppp_ll_addr[1] = 0x00;
		ppp_ll_addr[2] = 0x5E;
		ppp_ll_addr[3] = 0x00;
		ppp_ll_addr[4] = 0x53;
		ppp_ll_addr[5] = sys_rand32_get();
	}
	net_if_set_link_addr(ppp_iface, ppp_ll_addr, ll_addr_len, NET_LINK_UNKNOWN);

	return true;
}

static void send_status_notification(void)
{
	const bool is_running = atomic_get(&ppp_state) == PPP_STATE_RUNNING;

	rsp_send("\r\n#XPPP: %u,%u\r\n", is_running, ppp_peer_connected);
}

static int ppp_start_failure(int ret)
{
	close_ppp_sockets();
	net_if_down(ppp_iface);
	return ret;
}

static int ppp_start_internal(void)
{
	int ret;
	unsigned int mtu;
	struct ppp_context *const ctx = net_if_l2_data(ppp_iface);

	if (!configure_ppp_link_ip_addresses(ctx)) {
		return -EADDRNOTAVAIL;
	}

	ret = pdn_dynamic_params_get(PDP_CID, &ctx->ipcp.my_options.dns1_address,
				     &ctx->ipcp.my_options.dns2_address, &mtu);
	if (ret) {
		return ret;
	}

	if (mtu) {
		/* Set the PPP MTU to that of the LTE link. */
		mtu = MIN(mtu, sizeof(ppp_data_buf));
	} else {
		LOG_DBG("Could not retrieve MTU, using default.");
		mtu = sizeof(ppp_data_buf);
	}

	net_if_set_mtu(ppp_iface, mtu);
	LOG_DBG("MTU set to %u.", mtu);

	ret = net_if_up(ppp_iface);
	if (ret) {
		LOG_ERR("Failed to bring PPP interface up (%d).", ret);
		return ret;
	}

	if (!open_ppp_sockets()) {
		return ppp_start_failure(-ENOTCONN);
	}

#if defined(CONFIG_SLM_CMUX)
	ppp_pipe = slm_cmux_reserve(CMUX_PPP_CHANNEL);
	/* The pipe opening is managed by CMUX. */
#endif

	modem_ppp_attach(&ppp_module, ppp_pipe);

#if !defined(CONFIG_SLM_CMUX)
	ret = modem_pipe_open(ppp_pipe);
	if (ret) {
		LOG_ERR("Failed to open PPP pipe (%d).", ret);
		return ppp_start_failure(ret);
	}
#endif

	net_if_carrier_on(ppp_iface);

	LOG_INF("PPP started.");

	k_thread_create(&ppp_data_passing_thread_id, ppp_data_passing_thread_stack,
			K_THREAD_STACK_SIZEOF(ppp_data_passing_thread_stack),
			ppp_data_passing_thread, NULL, NULL, NULL,
			K_PRIO_COOP(10), 0, K_NO_WAIT);
	k_thread_name_set(&ppp_data_passing_thread_id, "ppp_data_passing");

	return 0;
}

bool slm_ppp_is_running(void)
{
	return atomic_get(&ppp_state) != PPP_STATE_STOPPED;
}

static void ppp_start(void)
{
	if (atomic_cas(&ppp_state, PPP_STATE_STOPPED, PPP_STATE_STARTING)) {
		if (ppp_start_internal()) {
			atomic_set(&ppp_state, PPP_STATE_STOPPED);
		} else {
			atomic_set(&ppp_state, PPP_STATE_RUNNING);
			send_status_notification();
		}
	}
}

static void ppp_stop_internal(void)
{
	LOG_DBG("Stopping PPP...");

	/* Bring the interface down before releasing pipes and carrier.
	 * This is needed for LCP to notify the remote endpoint that the link is going down.
	 */
	const int ret = net_if_down(ppp_iface);

	if (ret) {
		LOG_WRN("Failed to bring PPP interface down (%d).", ret);
	}

#if !defined(CONFIG_SLM_CMUX)
	modem_pipe_close(ppp_pipe);
#endif

	modem_ppp_release(&ppp_module);

#if defined(CONFIG_SLM_CMUX)
	slm_cmux_release(CMUX_PPP_CHANNEL);
#endif

	net_if_carrier_off(ppp_iface);

	close_ppp_sockets();

	k_thread_join(&ppp_data_passing_thread_id, K_SECONDS(1));

	LOG_INF("PPP stopped.");
}

static void ppp_stop(void)
{
	if (atomic_cas(&ppp_state, PPP_STATE_RUNNING, PPP_STATE_STOPPING)) {
		ppp_stop_internal();
		atomic_set(&ppp_state, PPP_STATE_STOPPED);
		send_status_notification();
	}
}

/* Automatically starts/stops PPP when the default PDN connection goes up/down. */
static void pdp_ctx_event_handler(uint8_t cid, enum pdn_event event, int reason)
{
	switch (event) {
	case PDN_EVENT_ACTIVATED:
		LOG_INF("Connection up. Starting PPP.");
		k_work_submit_to_queue(&slm_work_q, &ppp_restart_work.work);
		break;
	case PDN_EVENT_DEACTIVATED:
		LOG_DBG("Connection down.");
		ppp_stop();
		break;
	default:
		LOG_DBG("Default PDN connection event %d received.", event);
		break;
	}
}

static void ppp_controller(struct k_work *work)
{
	struct ppp_work *const ppp_work = CONTAINER_OF(work, struct ppp_work, work);

	switch (ppp_work->action) {
	case PPP_START:
		ppp_start();
		break;
	case PPP_RESTART:
		ppp_stop();
		ppp_start();
		break;
	case PPP_STOP:
		ppp_stop();
		break;
	default:
		LOG_ERR("Unknown PPP action: %d.", ppp_work->action);
		break;
	}
}

static void ppp_net_mgmt_event_handler(struct net_mgmt_event_callback *cb,
				       uint32_t mgmt_event, struct net_if *iface)
{
	switch (mgmt_event) {
	case NET_EVENT_PPP_PHASE_RUNNING:
		LOG_INF("Peer connected.");
		ppp_peer_connected = true;
		send_status_notification();
		break;
	case NET_EVENT_PPP_PHASE_DEAD:
		LOG_DBG("Peer not connected.");
		/* This event can come without prior NET_EVENT_PPP_PHASE_RUNNING. */
		if (!ppp_peer_connected) {
			break;
		}
		ppp_peer_connected = false;
		/* Also ignore this event when it is received after PPP has been stopped. */
		if (!slm_ppp_is_running()) {
			break;
		}
		send_status_notification();
		/* For the peer to be able to successfully reconnect
		 * (handshake issues observed with pppd and Windows dial-up),
		 * for some reason the Zephyr PPP link needs to be restarted.
		 */
		LOG_INF("Peer disconnected. Restarting PPP...");
		k_work_submit_to_queue(&slm_work_q, &ppp_restart_work.work);
		break;
	}
}

int slm_ppp_init(void)
{
#if !defined(CONFIG_SLM_CMUX)
	if (!device_is_ready(ppp_uart_dev)) {
		return -EAGAIN;
	}

	{
		static struct modem_backend_uart ppp_uart_backend;
		static uint8_t ppp_uart_backend_receive_buf[sizeof(ppp_data_buf)];
		static uint8_t ppp_uart_backend_transmit_buf[sizeof(ppp_data_buf)];

		const struct modem_backend_uart_config uart_backend_config = {
			.uart = ppp_uart_dev,
			.receive_buf = ppp_uart_backend_receive_buf,
			.receive_buf_size = sizeof(ppp_uart_backend_receive_buf),
			.transmit_buf = ppp_uart_backend_transmit_buf,
			.transmit_buf_size = sizeof(ppp_uart_backend_transmit_buf),
		};

		ppp_pipe = modem_backend_uart_init(&ppp_uart_backend, &uart_backend_config);
		if (!ppp_pipe) {
			return -ENOSYS;
		}
	}
#endif

	ppp_iface = modem_ppp_get_iface(&ppp_module);

	net_if_flag_set(ppp_iface, NET_IF_POINTOPOINT);

	pdn_default_ctx_cb_reg(pdp_ctx_event_handler);

	{
		static struct net_mgmt_event_callback ppp_net_mgmt_event_cb;

		net_mgmt_init_event_callback(&ppp_net_mgmt_event_cb, ppp_net_mgmt_event_handler,
					    NET_EVENT_PPP_PHASE_RUNNING | NET_EVENT_PPP_PHASE_DEAD);
		net_mgmt_add_event_callback(&ppp_net_mgmt_event_cb);
	}

	LOG_DBG("PPP initialized.");
	return 0;
}

SLM_AT_CMD_CUSTOM(xppp, "AT#XPPP", handle_at_ppp);
static int handle_at_ppp(enum at_cmd_type cmd_type, const struct at_param_list *param_list,
			 uint32_t param_count)
{
	int ret;
	unsigned int op;
	enum {
		OP_STOP,
		OP_START,
		OP_COUNT
	};

	if (cmd_type == AT_CMD_TYPE_READ_COMMAND) {
		send_status_notification();
		return 0;
	}
	if (cmd_type != AT_CMD_TYPE_SET_COMMAND || param_count != 2) {
		return -EINVAL;
	}

	ret = at_params_unsigned_int_get(param_list, 1, &op);
	if (ret) {
		return ret;
	} else if (op >= OP_COUNT) {
		return -EINVAL;
	}

	/* Send "OK" first in case stopping PPP results in the CMUX AT channel switching. */
	rsp_send_ok();
	if (op == OP_START) {
		k_work_submit_to_queue(&slm_work_q, &ppp_start_work.work);
	} else {
		k_work_submit_to_queue(&slm_work_q, &ppp_stop_work.work);
	}
	return -SILENT_AT_COMMAND_RET;
}

static void ppp_data_passing_thread(void*, void*, void*)
{
	const size_t mtu = net_if_get_mtu(ppp_iface);
	struct pollfd fds[PPP_FDS_COUNT];

	for (size_t i = 0; i != ARRAY_SIZE(fds); ++i) {
		fds[i].fd = ppp_fds[i];
		fds[i].events = POLLIN;
	}

	while (true) {
		const int poll_ret = poll(fds, ARRAY_SIZE(fds), -1);

		if (poll_ret <= 0) {
			LOG_ERR("Sockets polling failed (%d, %d).", poll_ret, errno);
			ppp_stop();
			return;
		}

		for (size_t src = 0; src != ARRAY_SIZE(fds); ++src) {
			const short revents = fds[src].revents;

			if (!revents) {
				continue;
			}
			if (!(revents & POLLIN)) {
				/* POLLERR/POLLNVAL happen when the sockets are closed
				 * or when the connection goes down.
				 */
				if ((revents ^ POLLERR) && (revents ^ POLLNVAL)) {
					LOG_WRN("Unexpected event 0x%x on %s socket.",
						revents, ppp_socket_names[src]);
				}
				ppp_stop();
				return;
			}
			const ssize_t len = recv(fds[src].fd, ppp_data_buf, mtu, MSG_DONTWAIT);

			if (len <= 0) {
				if (len != -1 || (errno != EAGAIN && errno != EWOULDBLOCK)) {
					LOG_ERR("Failed to receive data from %s socket (%d, %d).",
						ppp_socket_names[src], len, errno);
				}
				continue;
			}
			ssize_t send_ret;
			const size_t dst = (src == ZEPHYR_FD_IDX) ? MODEM_FD_IDX : ZEPHYR_FD_IDX;
			void *dst_addr = (dst == MODEM_FD_IDX) ? NULL : &ppp_zephyr_dst_addr;
			socklen_t addrlen = (dst == MODEM_FD_IDX) ? 0 : sizeof(ppp_zephyr_dst_addr);

			send_ret = sendto(fds[dst].fd, ppp_data_buf, len, 0, dst_addr, addrlen);
			if (send_ret == -1) {
				LOG_ERR("Failed to send %zd bytes to %s socket (%d).",
					len, ppp_socket_names[dst], errno);
			} else if (send_ret != len) {
				LOG_ERR("Only sent %zd out of %zd bytes to %s socket.",
					send_ret, len, ppp_socket_names[dst]);
			} else {
				LOG_DBG("Forwarded %zd bytes to %s socket.",
					send_ret, ppp_socket_names[dst]);
			}
		}
	}
}
```

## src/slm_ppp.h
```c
/*
 * Copyright (c) 2023 Nordic Semiconductor ASA
 *
 * SPDX-License-Identifier: LicenseRef-Nordic-5-Clause
 */
#ifndef SLM_PPP_
#define SLM_PPP_

#include <modem/at_cmd_parser.h>
#include <stdbool.h>

/** @retval 0 on success. */
int slm_ppp_init(void);

bool slm_ppp_is_running(void);

#endif
```
